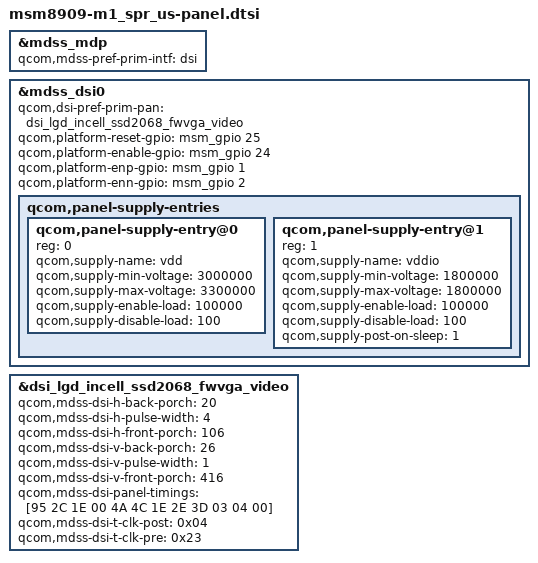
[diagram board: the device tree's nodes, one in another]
/* Copyright (c) 2013, Code Aurora Forum. All rights reserved.
 *
 * This program is free software; you can redistribute it and/or modify
 * it under the terms of the GNU General Public License version 2 and
 * only version 2 as published by the Free Software Foundation.
 *
 * This program is distributed in the hope that it will be useful,
 * but WITHOUT ANY WARRANTY; without even the implied warranty of
 * MERCHANTABILITY or FITNESS FOR A PARTICULAR PURPOSE.  See the
 * GNU General Public License for more details.
 */

#include "../msm8909-lge-common/dsi-panel-lgd-ssd2068-fwvga-video.dtsi"
#include "../msm8909-lge-common/msm8909-backlight-rt4832.dtsi"

&mdss_mdp {
		qcom,mdss-pref-prim-intf = "dsi";
};

&mdss_dsi0 {
		qcom,dsi-pref-prim-pan = <&dsi_lgd_incell_ssd2068_fwvga_video>;
		qcom,platform-reset-gpio = <&msm_gpio 25 0>;
		qcom,platform-enable-gpio = <&msm_gpio 24 0>;
		qcom,platform-enp-gpio = <&msm_gpio 1 0>;
		qcom,platform-enn-gpio = <&msm_gpio 2 0>;

		qcom,panel-supply-entries {
			#address-cells = <1>;
			#size-cells = <0>;

			qcom,panel-supply-entry@0 {
				reg = <0>;
				qcom,supply-name = "vdd";
				qcom,supply-min-voltage = <3000000>;
				qcom,supply-max-voltage = <3300000>;
				qcom,supply-enable-load = <100000>;
				qcom,supply-disable-load = <100>;
			};

			qcom,panel-supply-entry@1 {
				reg = <1>;
				qcom,supply-name = "vddio";
				qcom,supply-min-voltage = <1800000>;
				qcom,supply-max-voltage = <1800000>;
				qcom,supply-enable-load = <100000>;
				qcom,supply-disable-load = <100>;
				qcom,supply-post-on-sleep = <1>;
			};
		};
};

&dsi_lgd_incell_ssd2068_fwvga_video {
		qcom,mdss-dsi-h-back-porch = <20>;
		qcom,mdss-dsi-h-pulse-width = <4>;
		qcom,mdss-dsi-h-front-porch = <106>;

		qcom,mdss-dsi-v-back-porch = <26>;
		qcom,mdss-dsi-v-pulse-width = <1>;
		qcom,mdss-dsi-v-front-porch = <416>;

		qcom,mdss-dsi-panel-timings = [95 2C 1E 00 4A 4C 1E 2E 3D 03 04 00];
		qcom,mdss-dsi-t-clk-post = <0x04>;
		qcom,mdss-dsi-t-clk-pre = <0x23>;
};
